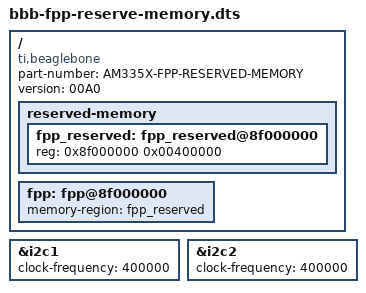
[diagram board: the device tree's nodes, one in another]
/dts-v1/;
/plugin/;

#include <dt-bindings/board/am335x-bbw-bbb-base.h>
#include <dt-bindings/pinctrl/am33xx.h>

/* Reserve 4M DDR memory for the pixel buffers */
/ {

    compatible = "ti,beaglebone", "ti,beaglebone-black", "ti,beaglebone-green";

    // identification
    part-number = "AM335X-FPP-RESERVED-MEMORY";
    version = "00A0";

	fragment@0 {
		target-path = "/";
		__overlay__ {
			reserved-memory {
				#address-cells = <1>;
				#size-cells = <1>;
				ranges;
				fpp_reserved: fpp_reserved@8f000000 {
					reg = <0x8f000000 0x00400000>;
					status = "okay"; 
				};      
			};
   
			fpp: fpp@8f000000 {
		                memory-region = <&fpp_reserved>;
			        status = "okay";
			};
		};
	};

	fragment@1 {
                target = <&i2c1>;
                __overlay__ {
                        status = "okay";
                        clock-frequency = <400000>;
		};
	};
        fragment@2 {
                target = <&i2c2>;
                __overlay__ {
                        status = "okay";
                        clock-frequency = <400000>;
                };
        };
};

